# GD32E502 register map
File version: 1.0
CPU: CM33 r0p4, little endian, MPU, FPU, 4 interrupt priority bits
Registers are 32-bit, read-write, reset 0x0 unless marked. A register's access mark holds for its fields unless they carry their own. Offsets are from the block's base; [hi:lo] are bit positions; {n}, {i} and the like mark numbered series.

## CRC — cyclic redundancy check calculation unit
Base 0x40023000
0x00 DATA reset 0xFFFFFFFF
  [31:0] DATA — CRC calculation result bits
0x04 FDATA — Free data register
  [7:0] FDATA — General-purpose 8-bit data register bits
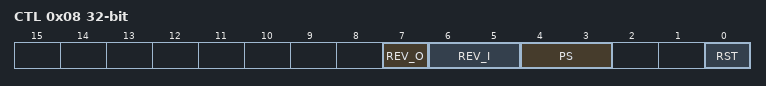
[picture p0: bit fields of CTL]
0x08 CTL — Control register
  [7] REV_O — Reverse output data
  [6:5] REV_I — Reverse input data
  [4:3] PS — Size of polynomial
  [0] RST — reset bit
0x10 IDATA reset 0xFFFFFFFF — Initialization Data Register
  [31:0] IDATA — CRC calculation initial value
0x14 POLY reset 0x4C11DB7 — Polynomial register
  [31:0] POLY — User configurable polynomial value

## DMA0 — DMA0 controller
Base 0x40020000
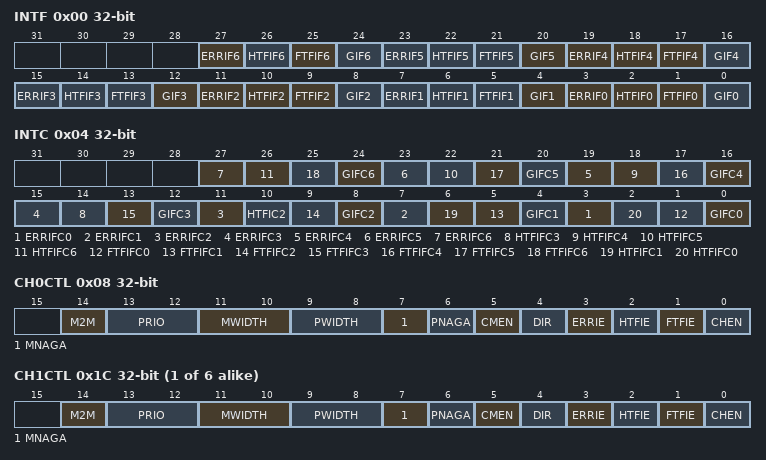
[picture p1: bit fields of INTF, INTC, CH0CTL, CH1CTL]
0x00 INTF ro — DMA interrupt flag register (DMA_INTF)
  [4n+3] ERRIF{n} (n=0..6) — Channel {n} Error flag
  [26] HTFIF6 — Channel 5 Half Transfer Finish flag
  [4n+1] FTFIF{n} (n=0..6) — Channel {n} Full Transfer Finish flag
  [4n] GIF{n} (n=0..6) — Channel {n} Global interrupt flag
  [4n+2] HTFIF{n} (n=0..5) — Channel {n} Half Transfer Finish flag
0x04 INTC wo — DMA interrupt flag clear register (DMA_INTC)
  [4n+3] ERRIFC{n} (n=0..6) — Channel {n} Error clear
  [4n+2] HTFIFC{n} (n=3..6) — Channel {n} Half Transfer clear
  [4n+1] FTFIFC{n} (n=0..6) — Channel {n} Full Transfer Finish clear
  [4n] GIFC{n} (n=0..6) — Channel {n} Global interrupt flag clear
  [10] HTFIC2 — Channel 2 Half Transfer clear
  [6] HTFIFC1 — Channel 1 Half Transfer clear
  [2] HTFIFC0 — Channel 0 Half Transfer clear
0x08 CH0CTL — DMA channel configuration register (DMA_CH0CTL)
  [14] M2M — Memory to memory mode
  [13:12] PRIO — Priority Level of this channel
  [11:10] MWIDTH — Transfer data size of memory
  [9:8] PWIDTH — Transfer data size of peripheral
  [7] MNAGA — Next address generation algorithm of memory
  [6] PNAGA — Next address generation algorithm of peripheral
  [5] CMEN — Circular mode enable
  [4] DIR — Transfer direction
  [3] ERRIE — Transfer access error interrupt enable
  [2] HTFIE — Half Transfer Finish interrupt enable
  [1] FTFIE — Full Transfer Finish interrupt enable
  [0] CHEN — Channel enable
{0xC+0x14*i} CH{i}CNT (i=0..6) — DMA channel {i} counter register
  [15:0] CNT — Transfer counter
{0x10+0x14*i} CH{i}PADDR (i=0..6) — DMA channel {i} peripheral base address register
  [31:0] PADDR — Peripheral base address
{0x14+0x14*i} CH{i}MADDR (i=0..6) — DMA channel {i} memory base address register
  [31:0] MADDR — Memory address
{0x8+0x14*i} CH{i}CTL (i=1..6) — DMA channel configuration register (DMA_CH{i}CTL)
  [14] M2M — Memory to memory mode
  [13:12] PRIO — Priority Level of this channel
  [11:10] MWIDTH — Transfer data size of memory
  [9:8] PWIDTH — Transfer data size of peripheral
  [7] MNAGA — Next address generation algorithm of memory
  [6] PNAGA — Next address generation algorithm of peripheral
  [5] CMEN — Circular mode enable
  [4] DIR — Transfer direction
  [3] ERRIE — Error interrupt enable
  [2] HTFIE — Half Transfer Finish interrupt enable
  [1] FTFIE — Full Transfer Finish interrupt enable
  [0] CHEN — Channel enable

## DMA1 — DMA controller
Base 0x40020400
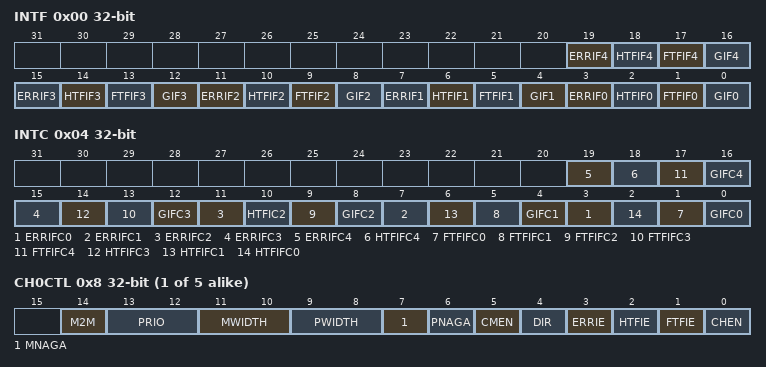
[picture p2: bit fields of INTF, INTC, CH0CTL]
0x00 INTF ro — Interrupt flag register
  [4n+3] ERRIF{n} (n=0..4) — Error flag of channel {n}
  [4n+2] HTFIF{n} (n=0..4) — Half transfer finish flag of channel {n}
  [4n+1] FTFIF{n} (n=0..4) — Full Transfer finish flag of channe {n}
  [4n] GIF{n} (n=0..4) — Global interrupt flag of channel {n}
0x04 INTC wo — Interrupt flag clear register
  [4n+3] ERRIFC{n} (n=0..4) — Clear bit for error flag of channel {n}
  [18] HTFIFC4 — Clear bit for half transfer finish flag of channel 4
  [4n+1] FTFIFC{n} (n=0..4) — Clear bit for full transfer finish flag of channel {n}
  [4n] GIFC{n} (n=0..4) — Clear global interrupt flag of channel {n}
  [14] HTFIFC3 — Clear bit for half transfer finish flag of channel 3
  [10] HTFIC2 — Clear bit for half transfer finish flag of channel 2
  [6] HTFIFC1 — Clear bit for half transfer finish flag of channel 1
  [2] HTFIFC0 — Clear bit for half transfer finish flag of channel 0
{0x8+0x14*i} CH{i}CTL (i=0..4) — Channel {i} control register
  [14] M2M — Memory to Memory Mode
  [13:12] PRIO — Priority level
  [11:10] MWIDTH — Transfer data size of memory
  [9:8] PWIDTH — Transfer data size of peripheral
  [7] MNAGA — Next address generation algorithm of memory
  [6] PNAGA — Next address generation algorithm of peripheral
  [5] CMEN — Circular mode enable
  [4] DIR — Transfer direction
  [3] ERRIE — Enable bit for channel error interrupt
  [2] HTFIE — Enable bit for channel half transfer finish interrupt
  [1] FTFIE — Enable bit for channel full transfer finish interrupt
  [0] CHEN — Channel enable
{0xC+0x14*i} CH{i}CNT (i=0..4) — Channel {i} counter register
  [15:0] CNT — Transfer counter
{0x10+0x14*i} CH{i}PADDR (i=0..4) — Channel {i} peripheral base address register
  [31:0] PADDR — Peripheral base address
{0x14+0x14*i} CH{i}MADDR (i=0..4) — Channel {i} memory base address register
  [31:0] MADDR — Memory base address
